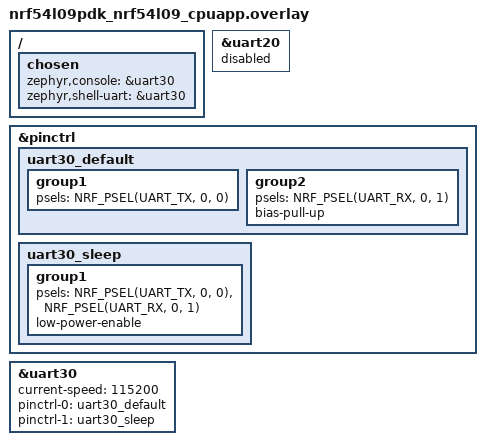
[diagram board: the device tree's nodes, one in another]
/*
 * Copyright (c) 2025 Nordic Semiconductor ASA
 *
 * SPDX-License-Identifier: LicenseRef-Nordic-5-Clause
 */

/ {
	chosen {
		zephyr,console = &uart30;
		zephyr,shell-uart = &uart30;
	};
};

&uart20 {
	status = "disabled";
};

&pinctrl {
	/omit-if-no-ref/ uart30_default: uart30_default {
		group1 {
			psels = <NRF_PSEL(UART_TX, 0, 0)>;
		};
		group2 {
			psels = <NRF_PSEL(UART_RX, 0, 1)>;
			bias-pull-up;
		};
	};

	/omit-if-no-ref/ uart30_sleep: uart30_sleep {
		group1 {
			psels = <NRF_PSEL(UART_TX, 0, 0)>,
				<NRF_PSEL(UART_RX, 0, 1)>;
			low-power-enable;
		};
	};
};

&uart30 {
	status = "okay";
	current-speed = <115200>;
	pinctrl-0 = <&uart30_default>;
	pinctrl-1 = <&uart30_sleep>;
	pinctrl-names = "default", "sleep";
};
